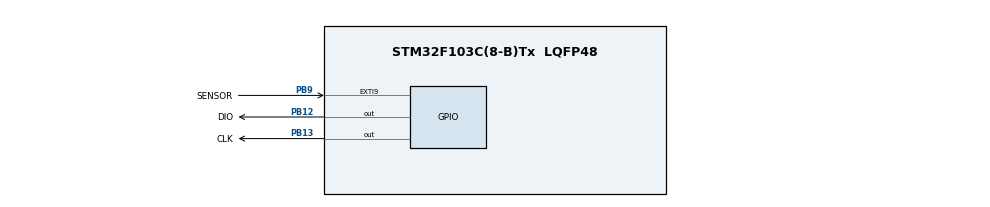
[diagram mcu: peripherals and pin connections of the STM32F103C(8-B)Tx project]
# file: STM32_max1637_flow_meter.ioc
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Mcu.Family=STM32F1
Mcu.Name=STM32F103C(8-B)Tx
Mcu.Package=LQFP48
NVIC.EXTI9_5_IRQn=true\:0\:0\:false\:false\:true
NVIC.PriorityGroup=NVIC_PRIORITYGROUP_4
PA13.Mode=Serial_Wire
PA13.Signal=SYS_JTMS-SWDIO
PA14.Mode=Serial_Wire
PA14.Signal=SYS_JTCK-SWCLK
PB12.GPIO_Label=DIO
PB12.Signal=GPIO_Output
PB13.GPIO_Label=CLK
PB13.Signal=GPIO_Output
PB9.GPIO_Label=SENSOR
PB9.Signal=GPXTI9
ProjectManager.HeapSize=0x200
ProjectManager.StackSize=0x400
ProjectManager.TargetToolchain=Makefile
RCC.AHBFreq_Value=8000000
RCC.APB1CLKDivider=RCC_HCLK_DIV16
RCC.APB1Freq_Value=500000
RCC.APB1TimFreq_Value=1000000
RCC.APB2CLKDivider=RCC_HCLK_DIV16
RCC.APB2Freq_Value=500000
RCC.APB2TimFreq_Value=1000000
RCC.HCLKFreq_Value=8000000

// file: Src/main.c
#include "main.h"
#include "stm32f1xx_hal.h"

/* USER CODE BEGIN Includes */
#include "1637.h"
/* USER CODE END Includes */

/* USER CODE BEGIN PV */
/* Private variables ---------------------------------------------------------*/
uint32_t adjust = 24000;
uint32_t counter;
uint32_t tim_counter; // external for timer - extern uint16_t tim_counter;
/* USER CODE END PV */

void SystemClock_Config(void);
static void MX_GPIO_Init(void);

/* USER CODE BEGIN PFP */
/* Private function prototypes -----------------------------------------------*/

/* USER CODE END PFP */

int main(void)
{

  /* MCU Configuration----------------------------------------------------------*/

  /* Reset of all peripherals, Initializes the Flash interface and the Systick. */
  HAL_Init();

  /* Configure the system clock */
  SystemClock_Config();

  /* Initialize all configured peripherals */
  MX_GPIO_Init();

  /* USER CODE BEGIN 2 */
  counter = 0;
  indication(8888);
  /* USER CODE END 2 */

  /* Infinite loop */
  while (1)
  {

  /* USER CODE BEGIN 3 */
    if(tim_counter>0&&tim_counter<=4)
    {
      counter++;
    }
    if(tim_counter>=4)
    {
      indication(adjust/(counter/1000));
      HAL_Delay(200);
      tim_counter=0;
      counter = 0;
    }

  }
  /* USER CODE END 3 */

}

/** System Clock Configuration
*/
void SystemClock_Config(void)
{

  RCC_OscInitTypeDef RCC_OscInitStruct;
  RCC_ClkInitTypeDef RCC_ClkInitStruct;

    /**Initializes the CPU, AHB and APB busses clocks
    */
  RCC_OscInitStruct.OscillatorType = RCC_OSCILLATORTYPE_HSI;
  RCC_OscInitStruct.HSIState = RCC_HSI_ON;
  RCC_OscInitStruct.HSICalibrationValue = 16;
  RCC_OscInitStruct.PLL.PLLState = RCC_PLL_NONE;
  if (HAL_RCC_OscConfig(&RCC_OscInitStruct) != HAL_OK)
  {
    _Error_Handler(__FILE__, __LINE__);
  }

    /**Initializes the CPU, AHB and APB busses clocks
    */
  RCC_ClkInitStruct.ClockType = RCC_CLOCKTYPE_HCLK|RCC_CLOCKTYPE_SYSCLK
                              |RCC_CLOCKTYPE_PCLK1|RCC_CLOCKTYPE_PCLK2;
  RCC_ClkInitStruct.SYSCLKSource = RCC_SYSCLKSOURCE_HSI;
  RCC_ClkInitStruct.AHBCLKDivider = RCC_SYSCLK_DIV1;
  RCC_ClkInitStruct.APB1CLKDivider = RCC_HCLK_DIV16;
  RCC_ClkInitStruct.APB2CLKDivider = RCC_HCLK_DIV16;

  if (HAL_RCC_ClockConfig(&RCC_ClkInitStruct, FLASH_LATENCY_0) != HAL_OK)
  {
    _Error_Handler(__FILE__, __LINE__);
  }

    /**Configure the Systick interrupt time
    */
  HAL_SYSTICK_Config(HAL_RCC_GetHCLKFreq()/1000);

    /**Configure the Systick
    */
  HAL_SYSTICK_CLKSourceConfig(SYSTICK_CLKSOURCE_HCLK);

  /* SysTick_IRQn interrupt configuration */
  HAL_NVIC_SetPriority(SysTick_IRQn, 0, 0);
}

/** Configure pins as
        * Analog
        * Input
        * Output
        * EVENT_OUT
        * EXTI
*/
static void MX_GPIO_Init(void)
{

  GPIO_InitTypeDef GPIO_InitStruct;

  /* GPIO Ports Clock Enable */
  __HAL_RCC_GPIOB_CLK_ENABLE();
  __HAL_RCC_GPIOA_CLK_ENABLE();

  /*Configure GPIO pin Output Level */
  HAL_GPIO_WritePin(GPIOB, DIO_Pin|CLK_Pin, GPIO_PIN_RESET);

  /*Configure GPIO pins : DIO_Pin CLK_Pin */
  GPIO_InitStruct.Pin = DIO_Pin|CLK_Pin;
  GPIO_InitStruct.Mode = GPIO_MODE_OUTPUT_PP;
  GPIO_InitStruct.Speed = GPIO_SPEED_FREQ_LOW;
  HAL_GPIO_Init(GPIOB, &GPIO_InitStruct);

  /*Configure GPIO pin : SENSOR_Pin */
  GPIO_InitStruct.Pin = SENSOR_Pin;
  GPIO_InitStruct.Mode = GPIO_MODE_IT_RISING;
  GPIO_InitStruct.Pull = GPIO_NOPULL;
  HAL_GPIO_Init(SENSOR_GPIO_Port, &GPIO_InitStruct);

  /* EXTI interrupt init*/
  HAL_NVIC_SetPriority(EXTI9_5_IRQn, 0, 0);
  HAL_NVIC_EnableIRQ(EXTI9_5_IRQn);

}

void _Error_Handler(char * file, int line)
{
  while(1)
  {
  }
}

/************************ (C) COPYRIGHT STMicroelectronics *****END OF FILE****/
